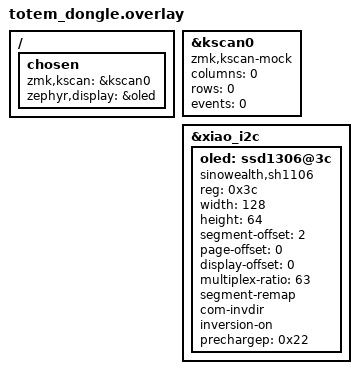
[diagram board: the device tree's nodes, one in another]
/*
 * Copyright (c) 2022 The ZMK Contributors
 *
 * SPDX-License-Identifier: MIT
 */

#include "totem.dtsi"

/ {
    chosen {
        zmk,kscan = &kscan0;
        zephyr,display = &oled;
    };


};

&kscan0 {
    compatible = "zmk,kscan-mock";
    columns = <0>;
    rows = <0>;
    events = <0>;
};

&xiao_i2c {
    status = "okay";
    
    oled: ssd1306@3c {
        compatible = "sinowealth,sh1106";
        reg = <0x3c>;
        width = <128>;
        height = <64>;
        segment-offset = <2>;
        page-offset = <0>;
        display-offset = <0>;
        multiplex-ratio = <63>;
        segment-remap;
        com-invdir;
        inversion-on;
        prechargep = <0x22>;
    };
};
